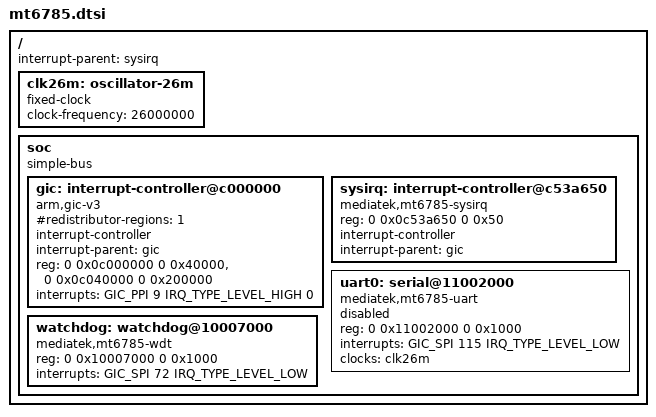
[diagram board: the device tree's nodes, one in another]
// SPDX-License-Identifier: (GPL-2.0 OR MIT)
// Copyright (c) 2025 Dinolek <git@dinolek.me>

#include <dt-bindings/interrupt-controller/arm-gic.h>
#include <dt-bindings/interrupt-controller/irq.h>

/ {
	#address-cells = <2>;
	#size-cells = <2>;
	interrupt-parent = <&sysirq>;

	clk26m: oscillator-26m {
		compatible = "fixed-clock";
		#clock-cells = <0>;
		clock-frequency = <26000000>;
	};

	soc {
		compatible = "simple-bus";
		#address-cells = <2>;
		#size-cells = <2>;
		ranges;

		gic: interrupt-controller@c000000 {
			compatible = "arm,gic-v3";
			#interrupt-cells = <4>;
			#redistributor-regions = <1>;
			interrupt-controller;
			interrupt-parent = <&gic>;
			reg = <0 0x0c000000 0 0x40000>,
			      <0 0x0c040000 0 0x200000>;
			interrupts = <GIC_PPI 9 IRQ_TYPE_LEVEL_HIGH 0>;
		};

		sysirq: interrupt-controller@c53a650 {
			compatible = "mediatek,mt6785-sysirq", "mediatek,mt6577-sysirq";
			reg = <0 0x0c53a650 0 0x50>;
			interrupt-controller;
			#interrupt-cells = <3>;
			interrupt-parent = <&gic>;
		};

		uart0: serial@11002000 {
			compatible = "mediatek,mt6785-uart", "mediatek,mt6577-uart";
			reg = <0 0x11002000 0 0x1000>;
			interrupts = <GIC_SPI 115 IRQ_TYPE_LEVEL_LOW>;
			clocks = <&clk26m>;
			clock-names = "baud";
			status = "disabled";
		};

		watchdog: watchdog@10007000 {
			compatible = "mediatek,mt6785-wdt";
			reg = <0 0x10007000 0 0x1000>;
			interrupts = <GIC_SPI 72 IRQ_TYPE_LEVEL_LOW>;
			#reset-cells = <1>;
		};
	};
};
